# CS32F031x register map
File version: 1.0
Registers are 32-bit, read-write, reset 0x0 unless marked. A register's access mark holds for its fields unless they carry their own. Offsets are from the block's base; [hi:lo] are bit positions.

## USART1 — Universal synchronous asynchronous receiver transmitter
Base 0x40013800
Same registers: USART2 0x40004400, USART3 0x40004800, USART4 0x40004C00, USART5 0x40005000, USART6 0x40011400, USART7 0x40011800, USART8 0x40011C00
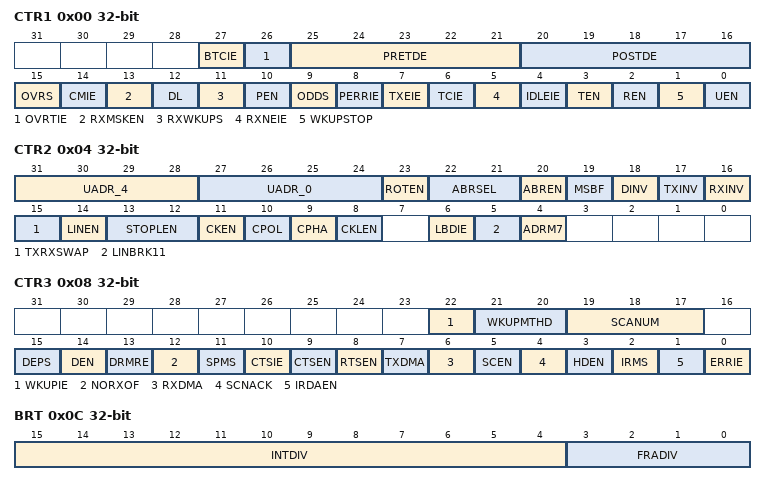
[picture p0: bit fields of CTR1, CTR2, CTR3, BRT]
0x00 CTR1 — Control register 1
  [27] BTCIE — Enable bit for Block transmit complete interrupt
  [26] OVRTIE — Enable bit for Receiver overtime interrupt
  [25:21] PRETDE — Pre-active time for Driver Enable
  [20:16] POSTDE — Pos-active time for Driver Enable
  [15] OVRS — Oversampling selection
  [14] CMIE — Enable bit for Character match interrupt
  [13] RXMSKEN — Reception mask mode enable
  [12] DL — Data length
  [11] RXWKUPS — Receiver wakeup selection
  [10] PEN — Parity enable
  [9] ODDS — Odd parity selection
  [8] PERRIE — Enable bit for parity err interrupt
  [7] TXEIE — Enable bit for transmit empty interrupt
  [6] TCIE — Enable bit for transmit complete interrupt
  [5] RXNEIE — Enable bit for RXNE interrupt
  [4] IDLEIE — Enable bit for IDLE interrupt
  [3] TEN — Transmitter enable
  [2] REN — Receiver enable
  [1] WKUPSTOP — Wakeup mcu from stop mode enable
  [0] UEN — USART enable
0x04 CTR2 — Control register 2
  [31:28] UADR_4 — USART Address
  [27:24] UADR_0 — USART Address
  [23] ROTEN — Receiver overtime enable
  [22:21] ABRSEL — Auto baud rate mode selection
  [20] ABREN — Auto baud rate enable
  [19] MSBF — MSB first
  [18] DINV — Data bit inversion
  [17] TXINV — TX pin inversion
  [16] RXINV — RX pin inversion
  [15] TXRXSWAP — TX/RX pins swap enable
  [14] LINEN — LIN mode enable
  [13:12] STOPLEN — STOP bits length
  [11] CKEN — CK pin enable
  [10] CPOL — Clock polarity
  [9] CPHA — Clock phase
  [8] CKLEN — LCK length
  [6] LBDIE — Enable bit for LIN break frame detection interrupt
  [5] LINBRK11 — 11-bit break frame detection
  [4] ADRM7 — 4bit/7bit Address Detection selection
0x08 CTR3 — Control register 3
  [22] WKUPIE — Enable bit for Wakeup from Stop mode interrupt
  [21:20] WKUPMTHD — Wakeup from Stop mode method
  [19:17] SCANUM — Number of Smartcard auto-retry times
  [15] DEPS — DE polarity selection
  [14] DEN — DE enable
  [13] DRMRE — DMA request mask on Reception Error
  [12] NORXOF — No Receive Overflow detection
  [11] SPMS — Sample method selection
  [10] CTSIE — Enable bit for CTS interrupt
  [9] CTSEN — CTS enable
  [8] RTSEN — RTS enable
  [7] TXDMA — Transmit with DMA
  [6] RXDMA — Receive with DMA
  [5] SCEN — Smartcard mode enable
  [4] SCNACK — Smartcard transmit NACK in parity error
  [3] HDEN — Half-duplex enable
  [2] IRMS — IrDA mode selection
  [1] IRDAEN — IrDA mode enable
  [0] ERRIE — Enable bit for Error interrupt
0x0C BRT — Baud rate register
  [15:4] INTDIV — DIV INT value
  [3:0] FRADIV — DIV Fraction value
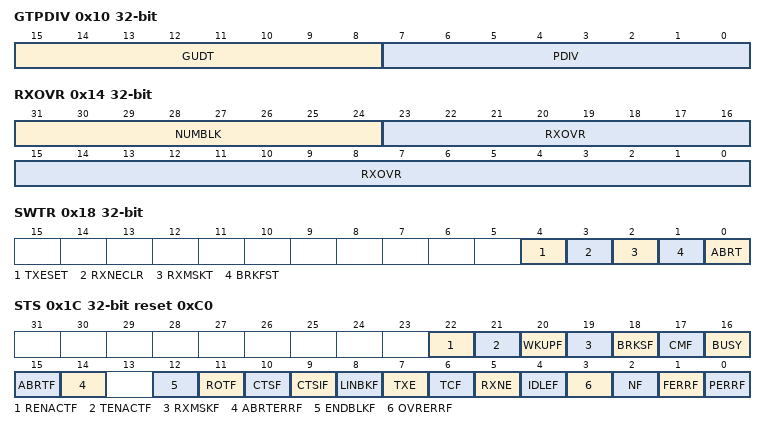
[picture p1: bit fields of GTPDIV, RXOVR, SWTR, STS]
0x10 GTPDIV — Guard time and pre-divider register
  [15:8] GUDT — Guard time value
  [7:0] PDIV — Pre-divider value
0x14 RXOVR — Receiver overtime register
  [31:24] NUMBLK — Unit number of block
  [23:0] RXOVR — Receiver overtime value
0x18 SWTR — Software Trigger register
  [4] TXESET — TXE set trigger
  [3] RXNECLR — RXNE clear trigger
  [2] RXMSKT — Reception mask mode trigger
  [1] BRKFST — Break frame send trigger
  [0] ABRT — Auto baud rate trigger
0x1C STS ro reset 0xC0 — Interrupt and status register
  [22] RENACTF — REN active flag
  [21] TENACTF — TEN active flag
  [20] WKUPF — Wakeup from Stop mode flag
  [19] RXMSKF — Reception mask mode flag
  [18] BRKSF — Break frame send flag
  [17] CMF — Character match flag
  [16] BUSY — Busy flag
  [15] ABRTF — Auto baud rate flag
  [14] ABRTERRF — Auto baud rate error flag
  [12] ENDBLKF — End of block flag
  [11] ROTF — Receiver overtime flag
  [10] CTSF — CTS flag
  [9] CTSIF — CTS interrupt flag
  [8] LINBKF — LIN break frame detection flag
  [7] TXE — transmit buffer empty flag
  [6] TCF — Transmission complete flag
  [5] RXNE — receiver buffer not empty flag
  [4] IDLEF — Idle frame detected flag
  [3] OVRERRF — Reception overflow error flag
  [2] NF — Noise flag
  [1] FERRF — Frame error flag
  [0] PERRF — Parity error flag
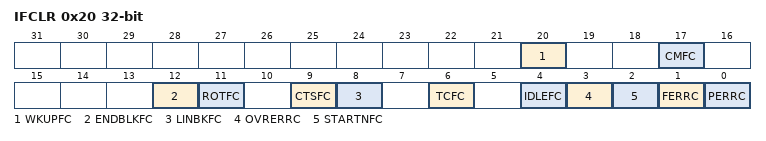
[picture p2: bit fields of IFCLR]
0x20 IFCLR — Interrupt flag clear register
  [20] WKUPFC — Wakeup from Stop mode flag clear
  [17] CMFC — Character match flag clear
  [12] ENDBLKFC — End of block flag clear
  [11] ROTFC — Receiver overtime flag clear
  [9] CTSFC — CTS flag clear
  [8] LINBKFC — LIN break frame detection flag clear
  [6] TCFC — Transmission complete flag clear
  [4] IDLEFC — Idle frame detected flag clear
  [3] OVRERRC — Overrun error flag clear
  [2] STARTNFC — Start bit Noise detected flag clear
  [1] FERRC — Frame error flag clear
  [0] PERRC — Parity error flag clear
0x24 RXBUF ro — Receive buffer register
  [8:0] RXBUF — Receive buffer
0x28 TXBUF — Transmit buffer register
  [8:0] TXBUF — Transmit buffer
